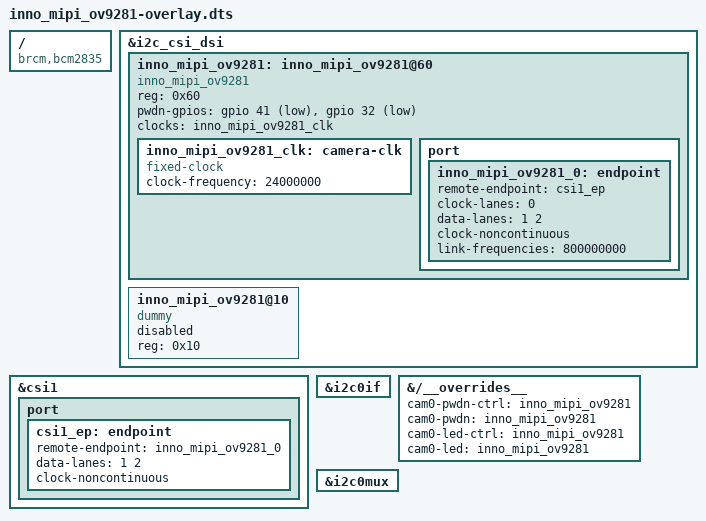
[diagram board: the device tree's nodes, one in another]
//
// Definitions for  MIPI OV9281 camera module on VC I2C bus
// 
// Copyright (C) 2022 SHENZHEN InnoMaker
//

/dts-v1/;
/plugin/;


/{
	compatible = "brcm,bcm2835";

	fragment@0 {
		target = <&i2c_csi_dsi>;
		__overlay__ {
			#address-cells = <1>;
			#size-cells = <0>;
			status = "okay";
			inno_mipi_ov9281: inno_mipi_ov9281@60 {
				compatible = "inno_mipi_ov9281";
				reg = <0x60>;
				status = "okay";

				pwdn-gpios = <&gpio 41 1>, <&gpio 32 1>;
				clocks = <&inno_mipi_ov9281_clk>;

				inno_mipi_ov9281_clk: camera-clk {
					compatible = "fixed-clock";
					#clock-cells = <0>;
					clock-frequency = <24000000>;
				};

				port {
					inno_mipi_ov9281_0: endpoint {
						remote-endpoint = <&csi1_ep>;
						clock-lanes = <0>;
						data-lanes = <1 2>;
						clock-noncontinuous;
						link-frequencies =
							/bits/ 64 <800000000>;
					};
				};
			};

			inno_mipi_ov9281@10 {
				compatible = "dummy";
				reg = <0x10>;
				status = "disabled";
			};
		};
	};

	fragment@1 {
		target = <&csi1>;
		__overlay__ {
			#address-cells = <1>;
			#size-cells = <0>;
			status = "okay";

			port {
				#address-cells = <1>;
				#size-cells = <0>;
				csi1_ep: endpoint {
					remote-endpoint = <&inno_mipi_ov9281_0>;
                                        data-lanes= <1 2>;
				        clock-noncontinuous;
				};
			};
		};
	};

	fragment@2 {
		target = <&i2c0_pins>;
		__dormant__ {
			brcm,pins = <28 29>;
			brcm,function = <4>; /* alt0 */
		};
	};
	fragment@3 {
		target = <&i2c0_pins>;
		__dormant__ {
			brcm,pins = <44 45>;
			brcm,function = <5>; /* alt1 */
		};
	};
	fragment@4 {
		target = <&i2c0if>;
		__overlay__ {
			status = "okay";
		};
	};

	fragment@5 {
		target-path="/__overrides__";
		__overlay__ {
			cam0-pwdn-ctrl = <&inno_mipi_ov9281>,"pwdn-gpios:0";
			cam0-pwdn      = <&inno_mipi_ov9281>,"pwdn-gpios:4";
			cam0-led-ctrl  = <&inno_mipi_ov9281>,"pwdn-gpios:12";
			cam0-led       = <&inno_mipi_ov9281>,"pwdn-gpios:16";
		};
	};
      fragment@6{
            target=<&i2c0mux>;
                 __overlay__ {

            status="okay";
         };

       };

	__overrides__ {
		i2c_pins_28_29 = <0>,"+2-3";
	};
};
